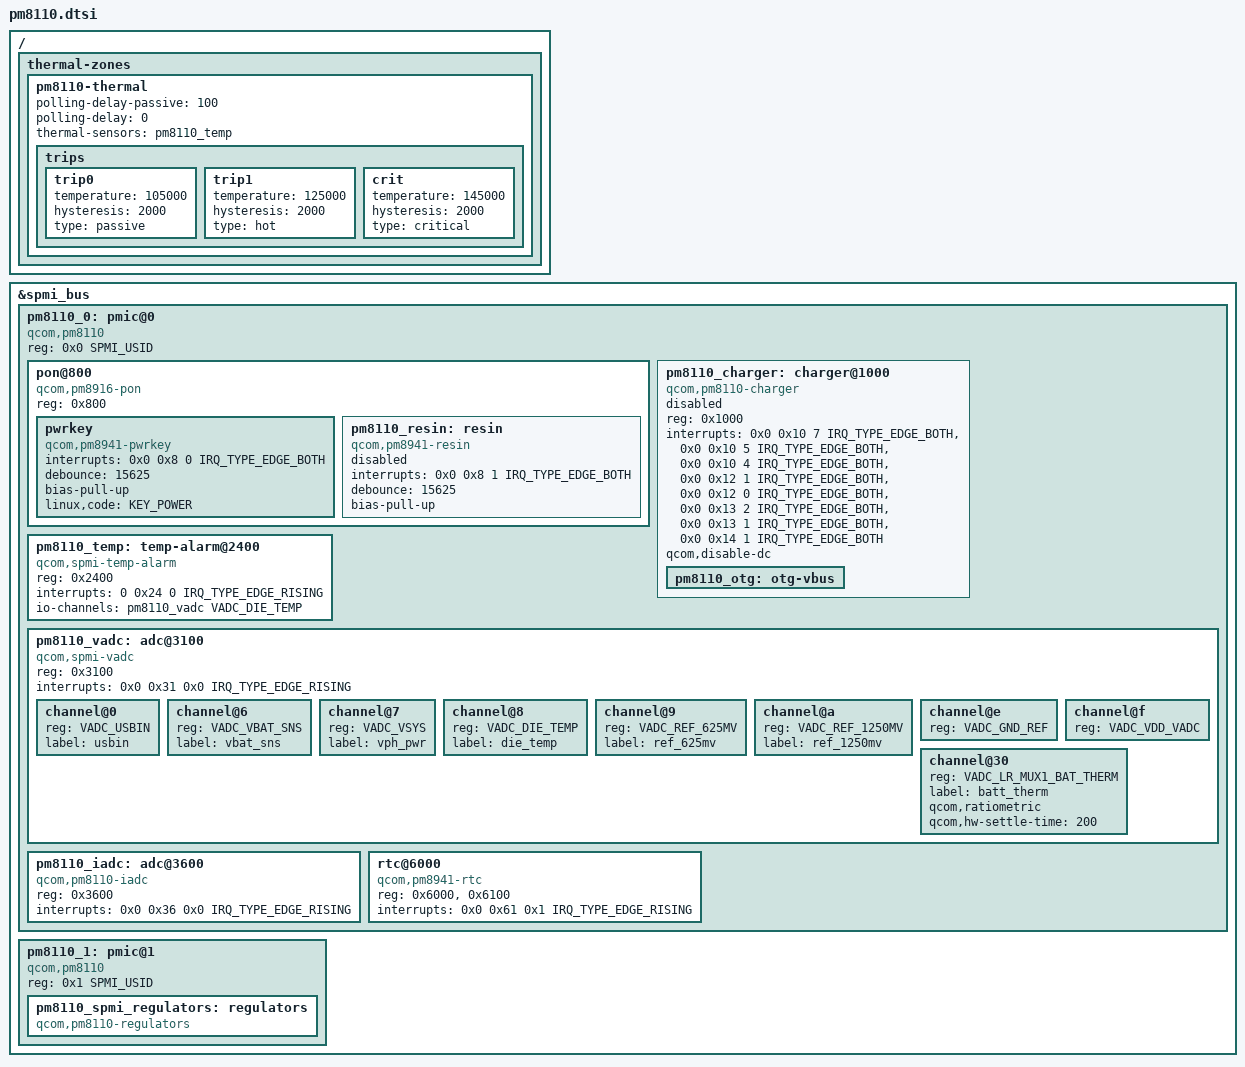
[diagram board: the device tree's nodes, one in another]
// SPDX-License-Identifier: BSD-3-Clause
#include <dt-bindings/iio/qcom,spmi-vadc.h>
#include <dt-bindings/input/linux-event-codes.h>
#include <dt-bindings/interrupt-controller/irq.h>
#include <dt-bindings/spmi/spmi.h>

/ {
	thermal-zones {
		pm8110-thermal {
			polling-delay-passive = <100>;
			polling-delay = <0>;
			thermal-sensors = <&pm8110_temp>;

			trips {
				trip0 {
					temperature = <105000>;
					hysteresis = <2000>;
					type = "passive";
				};

				trip1 {
					temperature = <125000>;
					hysteresis = <2000>;
					type = "hot";
				};

				crit {
					temperature = <145000>;
					hysteresis = <2000>;
					type = "critical";
				};
			};
		};
	};
};

&spmi_bus {
	pm8110_0: pmic@0 {
		compatible = "qcom,pm8110", "qcom,spmi-pmic";
		reg = <0x0 SPMI_USID>;
		#address-cells = <1>;
		#size-cells = <0>;

		pon@800 {
			compatible = "qcom,pm8916-pon";
			reg = <0x800>;

			pwrkey {
				compatible = "qcom,pm8941-pwrkey";
				interrupts = <0x0 0x8 0 IRQ_TYPE_EDGE_BOTH>;
				debounce = <15625>;
				bias-pull-up;
				linux,code = <KEY_POWER>;
			};

			pm8110_resin: resin {
				compatible = "qcom,pm8941-resin";
				interrupts = <0x0 0x8 1 IRQ_TYPE_EDGE_BOTH>;
				debounce = <15625>;
				bias-pull-up;
				status = "disabled";
			};
		};

		pm8110_charger: charger@1000 {
			compatible = "qcom,pm8110-charger", "qcom,pm8226-charger";
			reg = <0x1000>;
			interrupts = <0x0 0x10 7 IRQ_TYPE_EDGE_BOTH>,
				     <0x0 0x10 5 IRQ_TYPE_EDGE_BOTH>,
				     <0x0 0x10 4 IRQ_TYPE_EDGE_BOTH>,
				     <0x0 0x12 1 IRQ_TYPE_EDGE_BOTH>,
				     <0x0 0x12 0 IRQ_TYPE_EDGE_BOTH>,
				     <0x0 0x13 2 IRQ_TYPE_EDGE_BOTH>,
				     <0x0 0x13 1 IRQ_TYPE_EDGE_BOTH>,
				     <0x0 0x14 1 IRQ_TYPE_EDGE_BOTH>;
			interrupt-names = "chg-done",
					  "chg-fast",
					  "chg-trkl",
					  "bat-temp-ok",
					  "bat-present",
					  "chg-gone",
					  "usb-valid",
					  "dc-valid";

			/* There is no DC input */
			qcom,disable-dc;

			status = "disabled";

			pm8110_otg: otg-vbus { };
		};

		pm8110_temp: temp-alarm@2400 {
			compatible = "qcom,spmi-temp-alarm";
			reg = <0x2400>;
			interrupts = <0 0x24 0 IRQ_TYPE_EDGE_RISING>;
			io-channels = <&pm8110_vadc VADC_DIE_TEMP>;
			io-channel-names = "thermal";
			#thermal-sensor-cells = <0>;
		};

		pm8110_vadc: adc@3100 {
			compatible = "qcom,spmi-vadc";
			reg = <0x3100>;
			interrupts = <0x0 0x31 0x0 IRQ_TYPE_EDGE_RISING>;
			#address-cells = <1>;
			#size-cells = <0>;
			#io-channel-cells = <1>;

			channel@0 {
				reg = <VADC_USBIN>;
				label = "usbin";
			};

			channel@6 {
				reg = <VADC_VBAT_SNS>;
				label = "vbat_sns";
			};

			channel@7 {
				reg = <VADC_VSYS>;
				label = "vph_pwr";
			};

			channel@8 {
				reg = <VADC_DIE_TEMP>;
				label = "die_temp";
			};

			channel@9 {
				reg = <VADC_REF_625MV>;
				label = "ref_625mv";
			};

			channel@a {
				reg = <VADC_REF_1250MV>;
				label = "ref_1250mv";
			};

			channel@e {
				reg = <VADC_GND_REF>;
			};

			channel@f {
				reg = <VADC_VDD_VADC>;
			};

			channel@30 {
				reg = <VADC_LR_MUX1_BAT_THERM>;
				label = "batt_therm";
				qcom,ratiometric;
				qcom,hw-settle-time = <200>;
			};
		};

		pm8110_iadc: adc@3600 {
			compatible = "qcom,pm8110-iadc", "qcom,spmi-iadc";
			reg = <0x3600>;
			interrupts = <0x0 0x36 0x0 IRQ_TYPE_EDGE_RISING>;
			#io-channel-cells = <1>;
		};

		rtc@6000 {
			compatible = "qcom,pm8941-rtc";
			reg = <0x6000>, <0x6100>;
			reg-names = "rtc", "alarm";
			interrupts = <0x0 0x61 0x1 IRQ_TYPE_EDGE_RISING>;
		};
	};

	pm8110_1: pmic@1 {
		compatible = "qcom,pm8110", "qcom,spmi-pmic";
		reg = <0x1 SPMI_USID>;
		#address-cells = <1>;
		#size-cells = <0>;

		pm8110_spmi_regulators: regulators {
			compatible = "qcom,pm8110-regulators";
		};
	};
};
